AUTOSAR XML (schema 4-0-3)
standard types defined: Boolean, UInt32
package /AUTOSAR_Platform/DataConstrs
  range DC_Boolean: raw 0..1
package /PATAC/MSM/ComponentTypes
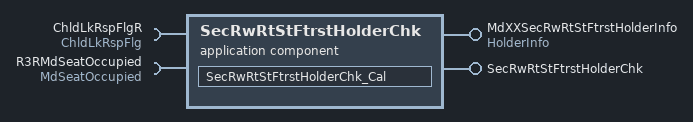
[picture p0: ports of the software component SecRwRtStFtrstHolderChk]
  application sw component type SecRwRtStFtrstHolderChk
    provide port MdXXSecRwRtStFtrstHolderInfo: nonqueued-sender-com-spec{data-element=HolderInfo/Val, init-value=0}, provided-interface=HolderInfo
    provide port SecRwRtStFtrstHolderChk: server-com-spec{operation=Cal, queue-length=1}, provided-interface=SecRwRtStFtrstHolderChk
    require port ChldLkRspFlgR: nonqueued-receiver-com-spec{data-element=ChldLkRspFlg/Val, filter=data-filter-type=ALWAYS, init-value=0}, required-interface=ChldLkRspFlg
    require port R3RMdSeatOccupied: nonqueued-receiver-com-spec{data-element=MdSeatOccupied/Val, filter=data-filter-type=ALWAYS, init-value=0}, required-interface=MdSeatOccupied
    behavior SecRwRtStFtrstHolderChk_InternalBehavior
      operation invoked event OIT_SecRwRtStFtrstHolderChk_Cal_SecRwRtStFtrstHolderChk_Cal: start-on-event=SecRwRtStFtrstHolderChk_Cal, operation=SecRwRtStFtrstHolderChk.Cal
      runnable SecRwRtStFtrstHolderChk_Cal
        data-receive-point-by-arguments:
          access REC_ChldLkRspFlgR_Val: accessed-variable=ChldLkRspFlgR.Val
          access REC_R3RMdSeatOccupied_Val: accessed-variable=R3RMdSeatOccupied.Val
        data-send-points:
          access SEND_MdXXSecRwRtStFtrstHolderInfo_Val: accessed-variable=MdXXSecRwRtStFtrstHolderInfo.Val
  swc implementation SecRwRtStFtrstHolderChk_Implementation: behavior=SecRwRtStFtrstHolderChk_InternalBehavior
    code-descriptors:
      code Default: artifact-descriptors=autosar-engineering-object={short-label=Default, category=SWSRC}
package /PATAC/MSM/ModeAdjust/PortInterface
  client server interface SecRwRtStFtrstHolderChk
    operation Cal
  sender receiver interface ChldLkRspFlg: invalidation-policy{data-element=ChldLkRspFlg/Val, handle-invalid=DONT-INVALIDATE}
    data Val: type=Boolean
  sender receiver interface HolderInfo: invalidation-policy{data-element=HolderInfo/Val, handle-invalid=DONT-INVALIDATE}
    data Val: type=UInt32
  sender receiver interface MdSeatOccupied: invalidation-policy{data-element=MdSeatOccupied/Val, handle-invalid=DONT-INVALIDATE}
    data Val: type=Boolean
